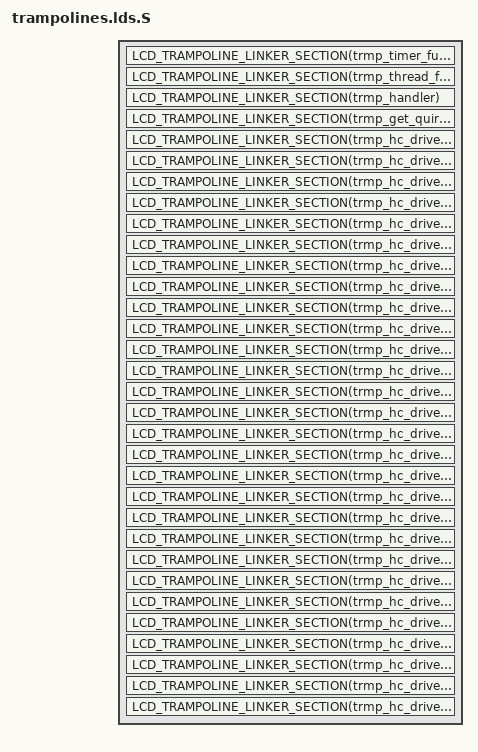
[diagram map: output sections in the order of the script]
#include <liblcd/trampoline_link.h>

SECTIONS{
	LCD_TRAMPOLINE_LINKER_SECTION(trmp_timer_func)
	LCD_TRAMPOLINE_LINKER_SECTION(trmp_thread_fn)
	LCD_TRAMPOLINE_LINKER_SECTION(trmp_handler)
	LCD_TRAMPOLINE_LINKER_SECTION(trmp_get_quirks)
	LCD_TRAMPOLINE_LINKER_SECTION(trmp_hc_driver_enable_device)
	LCD_TRAMPOLINE_LINKER_SECTION(trmp_hc_driver_update_hub_device)
	LCD_TRAMPOLINE_LINKER_SECTION(trmp_hc_driver_reset_device)
	LCD_TRAMPOLINE_LINKER_SECTION(trmp_hc_driver_update_device)
	LCD_TRAMPOLINE_LINKER_SECTION(trmp_hc_driver_set_usb2_hw_lpm)
	LCD_TRAMPOLINE_LINKER_SECTION(trmp_hc_driver_enable_usb3_lpm_timeout)
	LCD_TRAMPOLINE_LINKER_SECTION(trmp_hc_driver_disable_usb3_lpm_timeout)
	LCD_TRAMPOLINE_LINKER_SECTION(trmp_hc_driver_find_raw_port_number)
	LCD_TRAMPOLINE_LINKER_SECTION(trmp_hc_driver_stop)
	LCD_TRAMPOLINE_LINKER_SECTION(trmp_hc_driver_shutdown)
	LCD_TRAMPOLINE_LINKER_SECTION(trmp_hc_driver_get_frame_number)
	LCD_TRAMPOLINE_LINKER_SECTION(trmp_hc_driver_urb_enqueue)
	LCD_TRAMPOLINE_LINKER_SECTION(trmp_hc_driver_urb_dequeue)
	LCD_TRAMPOLINE_LINKER_SECTION(trmp_hc_driver_endpoint_reset)
	LCD_TRAMPOLINE_LINKER_SECTION(trmp_hc_driver_alloc_dev)
	LCD_TRAMPOLINE_LINKER_SECTION(trmp_hc_driver_free_dev)
	LCD_TRAMPOLINE_LINKER_SECTION(trmp_hc_driver_alloc_streams)
	LCD_TRAMPOLINE_LINKER_SECTION(trmp_hc_driver_free_streams)
	LCD_TRAMPOLINE_LINKER_SECTION(trmp_hc_driver_add_endpoint)
	LCD_TRAMPOLINE_LINKER_SECTION(trmp_hc_driver_drop_endpoint)
	LCD_TRAMPOLINE_LINKER_SECTION(trmp_hc_driver_check_bandwidth)
	LCD_TRAMPOLINE_LINKER_SECTION(trmp_hc_driver_reset_bandwidth)
	LCD_TRAMPOLINE_LINKER_SECTION(trmp_hc_driver_address_device)
	LCD_TRAMPOLINE_LINKER_SECTION(trmp_hc_driver_hub_status_data)
	LCD_TRAMPOLINE_LINKER_SECTION(trmp_hc_driver_irq)
	LCD_TRAMPOLINE_LINKER_SECTION(trmp_hc_driver_hub_control)
	LCD_TRAMPOLINE_LINKER_SECTION(trmp_hc_driver_reset)
	LCD_TRAMPOLINE_LINKER_SECTION(trmp_hc_driver_start)
}

INSERT AFTER .text
